AUTOSAR XML (schema 4-2-2)
package /Components
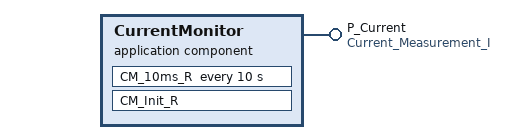
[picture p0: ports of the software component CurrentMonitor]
  application sw component type CurrentMonitor
    provide port P_Current: provided-interface=Current_Measurement_I
    behavior CurrentMonitor_InternalBehavior
      init event CM_Init_Event: start-on-event=CM_Init_R
      timing event CM_10ms_Event: start-on-event=CM_10ms_R, period=10
      runnable CM_Init_R
        data-send-points:
          access VA_CM_Init_Current: accessed-variable=P_Current.current_mA
      runnable CM_10ms_R: minimum-start-interval=10
        data-send-points:
          access VA_CM_Periodic_Current: accessed-variable=P_Current.current_mA
